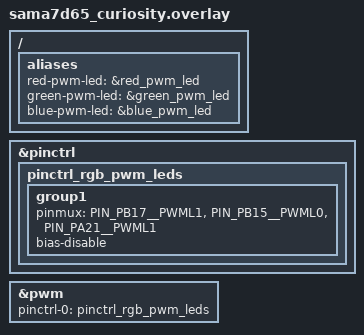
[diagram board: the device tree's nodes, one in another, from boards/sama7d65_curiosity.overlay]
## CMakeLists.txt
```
# SPDX-License-Identifier: Apache-2.0

cmake_minimum_required(VERSION 3.28.0)
find_package(Zephyr REQUIRED HINTS $ENV{ZEPHYR_BASE})
project(rgb_led)

target_sources(app PRIVATE src/main.c)
```

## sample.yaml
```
sample:
  name: RGB LED
tests:
  sample.basic.rgb_led:
    filter: dt_alias_exists("red-pwm-led") and dt_alias_exists("green-pwm-led")
      and dt_alias_exists("blue-pwm-led")
    tags:
      - drivers
      - pwm
    depends_on: pwm
    harness: led
    integration_platforms:
      - nrf52840_mdk/nrf52840
```

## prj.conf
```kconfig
CONFIG_PRINTK=y
CONFIG_PWM=y
CONFIG_LOG=y
```

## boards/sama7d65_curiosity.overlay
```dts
/*
 * Copyright (c) 2026 Microchip Technology Inc.
 *
 * SPDX-License-Identifier: Apache-2.0
 */

/ {
	aliases {
		red-pwm-led = &red_pwm_led;
		green-pwm-led = &green_pwm_led;
		blue-pwm-led = &blue_pwm_led;
	};
};

&pinctrl {
	pinctrl_rgb_pwm_leds: pinctrl_rgb_pwm_leds {
		group1 {
			pinmux = <PIN_PB17__PWML1>, /* LED red */
				 <PIN_PB15__PWML0>, /* LED green */
				 <PIN_PA21__PWML1>; /* LED blue */
			bias-disable;
		};
	};
};

&pwm {
	pinctrl-0 = <&pinctrl_rgb_pwm_leds>;
};
```

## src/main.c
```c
/*
 * Copyright (c) 2016 Intel Corporation
 *
 * SPDX-License-Identifier: Apache-2.0
 */

/**
 * @file Sample app to demonstrate PWM-based RGB LED control
 */

#include <zephyr/kernel.h>
#include <zephyr/sys/printk.h>
#include <zephyr/device.h>
#include <zephyr/drivers/pwm.h>

static const struct pwm_dt_spec red_pwm_led =
	PWM_DT_SPEC_GET(DT_ALIAS(red_pwm_led));
static const struct pwm_dt_spec green_pwm_led =
	PWM_DT_SPEC_GET(DT_ALIAS(green_pwm_led));
static const struct pwm_dt_spec blue_pwm_led =
	PWM_DT_SPEC_GET(DT_ALIAS(blue_pwm_led));

#define NUM_STEPS 8U

int main(void)
{
	uint32_t pulse_red, pulse_green, pulse_blue; /* pulse widths */
	int ret;

	const uint32_t step_red = red_pwm_led.period / NUM_STEPS;
	const uint32_t step_green = green_pwm_led.period / NUM_STEPS;
	const uint32_t step_blue = blue_pwm_led.period / NUM_STEPS;

	printk("PWM-based RGB LED control\n");

	if (!pwm_is_ready_dt(&red_pwm_led) ||
	    !pwm_is_ready_dt(&green_pwm_led) ||
	    !pwm_is_ready_dt(&blue_pwm_led)) {
		printk("Error: one or more PWM devices not ready\n");
		return 0;
	}

	while (1) {
		for (pulse_red = 0U; pulse_red <= red_pwm_led.period; pulse_red += step_red) {
			ret = pwm_set_pulse_dt(&red_pwm_led, pulse_red);
			if (ret != 0) {
				printk("Error %d: red write failed\n", ret);
				return 0;
			}

			for (pulse_green = 0U; pulse_green <= green_pwm_led.period;
			     pulse_green += step_green) {
				ret = pwm_set_pulse_dt(&green_pwm_led,
						       pulse_green);
				if (ret != 0) {
					printk("Error %d: green write failed\n",
					       ret);
					return 0;
				}

				for (pulse_blue = 0U; pulse_blue <= blue_pwm_led.period;
				     pulse_blue += step_blue) {
					ret = pwm_set_pulse_dt(&blue_pwm_led,
							       pulse_blue);
					if (ret != 0) {
						printk("Error %d: "
						       "blue write failed\n",
						       ret);
						return 0;
					}
					k_sleep(K_SECONDS(1));
				}
			}
		}
	}
	return 0;
}
```
